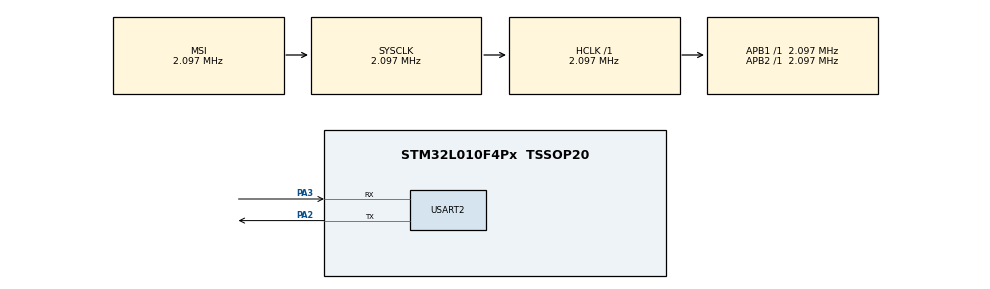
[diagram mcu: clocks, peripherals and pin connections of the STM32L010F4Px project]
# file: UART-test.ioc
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Mcu.Family=STM32L0
Mcu.Name=STM32L010F4Px
Mcu.Package=TSSOP20
NVIC.USART2_IRQn=true\:0\:0\:false\:false\:true\:true\:true
PA2.Mode=Asynchronous
PA2.Signal=USART2_TX
PA3.Mode=Asynchronous
PA3.Signal=USART2_RX
ProjectManager.HeapSize=0x200
ProjectManager.StackSize=0x400
ProjectManager.TargetToolchain=STM32CubeIDE
RCC.AHBFreq_Value=2097000
RCC.APB1Freq_Value=2097000
RCC.APB1TimFreq_Value=2097000
RCC.APB2Freq_Value=2097000
RCC.APB2TimFreq_Value=2097000
RCC.HSE_VALUE=8000000
RCC.HSI16_VALUE=16000000
RCC.HSI_VALUE=16000000
RCC.LSE_VALUE=32768
RCC.MSI_VALUE=2097000
RCC.SYSCLKFreq_VALUE=2097000
RCC.VCOOutputFreq_Value=48000000
USART2.VirtualMode=VM_ASYNC
board=custom

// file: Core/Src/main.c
/* USER CODE BEGIN Header */
/**
 ******************************************************************************
 * @file           : main.c
 * @brief          : Main program body
 ******************************************************************************
 * @attention
 *
 * <h2><center>&copy; Copyright (c) 2021 STMicroelectronics.
 * All rights reserved.</center></h2>
 *
 * This software component is licensed by ST under BSD 3-Clause license,
 * the "License"; You may not use this file except in compliance with the
 * License. You may obtain a copy of the License at:
 *                        opensource.org/licenses/BSD-3-Clause
 *
 ******************************************************************************
 */
/* USER CODE END Header */
#include "main.h"

/* USER CODE BEGIN Includes */
#define USART_RX_BUFFSIZE 10

static UART_HandleTypeDef *pHuart;
static uint8_t RxBuff[USART_RX_BUFFSIZE];
static uint32_t rd_ptr;

int gUartReceived = 0;
/* USER CODE END Includes */

UART_HandleTypeDef huart2;

void SystemClock_Config(void);
static void MX_GPIO_Init(void);
static void MX_USART2_UART_Init(void);
/* USER CODE BEGIN PFP */
void HAL_UART_RxCpltCallback(UART_HandleTypeDef *huart) {
	gUartReceived = 1;
}
/* USER CODE END PFP */

int main(void) {

	/* MCU Configuration--------------------------------------------------------*/

	/* Reset of all peripherals, Initializes the Flash interface and the Systick. */
	HAL_Init();

	/* Configure the system clock */
	SystemClock_Config();

	/* Initialize all configured peripherals */
	MX_GPIO_Init();
	MX_USART2_UART_Init();
	/* USER CODE BEGIN 2 */
	uint8_t buffer[256];
	/* USER CODE END 2 */

	/* Infinite loop */
	while (1) {

		/* USER CODE BEGIN 3 */
		HAL_UART_Receive_IT(&huart2, buffer, 1);
		HAL_UART_Transmit_IT(&huart2, buffer, 1);

		gUartReceived = 0;
	}
	/* USER CODE END 3 */
}

void SystemClock_Config(void) {
	RCC_OscInitTypeDef RCC_OscInitStruct = { 0 };
	RCC_ClkInitTypeDef RCC_ClkInitStruct = { 0 };
	RCC_PeriphCLKInitTypeDef PeriphClkInit = { 0 };

	/** Configure the main internal regulator output voltage
	 */
	__HAL_PWR_VOLTAGESCALING_CONFIG(PWR_REGULATOR_VOLTAGE_SCALE1);
	/** Initializes the RCC Oscillators according to the specified parameters
	 * in the RCC_OscInitTypeDef structure.
	 */
	RCC_OscInitStruct.OscillatorType = RCC_OSCILLATORTYPE_MSI;
	RCC_OscInitStruct.MSIState = RCC_MSI_ON;
	RCC_OscInitStruct.MSICalibrationValue = 0;
	RCC_OscInitStruct.MSIClockRange = RCC_MSIRANGE_5;
	RCC_OscInitStruct.PLL.PLLState = RCC_PLL_NONE;
	if (HAL_RCC_OscConfig(&RCC_OscInitStruct) != HAL_OK) {
		Error_Handler();
	}
	/** Initializes the CPU, AHB and APB buses clocks
	 */
	RCC_ClkInitStruct.ClockType = RCC_CLOCKTYPE_HCLK | RCC_CLOCKTYPE_SYSCLK
			| RCC_CLOCKTYPE_PCLK1 | RCC_CLOCKTYPE_PCLK2;
	RCC_ClkInitStruct.SYSCLKSource = RCC_SYSCLKSOURCE_MSI;
	RCC_ClkInitStruct.AHBCLKDivider = RCC_SYSCLK_DIV1;
	RCC_ClkInitStruct.APB1CLKDivider = RCC_HCLK_DIV1;
	RCC_ClkInitStruct.APB2CLKDivider = RCC_HCLK_DIV1;

	if (HAL_RCC_ClockConfig(&RCC_ClkInitStruct, FLASH_LATENCY_0) != HAL_OK) {
		Error_Handler();
	}
	PeriphClkInit.PeriphClockSelection = RCC_PERIPHCLK_USART2;
	PeriphClkInit.Usart2ClockSelection = RCC_USART2CLKSOURCE_PCLK1;
	if (HAL_RCCEx_PeriphCLKConfig(&PeriphClkInit) != HAL_OK) {
		Error_Handler();
	}
}

static void MX_USART2_UART_Init(void) {

	huart2.Instance = USART2;
	huart2.Init.BaudRate = 115200;
	huart2.Init.WordLength = UART_WORDLENGTH_8B;
	huart2.Init.StopBits = UART_STOPBITS_1;
	huart2.Init.Parity = UART_PARITY_NONE;
	huart2.Init.Mode = UART_MODE_TX_RX;
	huart2.Init.HwFlowCtl = UART_HWCONTROL_NONE;
	huart2.Init.OverSampling = UART_OVERSAMPLING_16;
	huart2.Init.OneBitSampling = UART_ONE_BIT_SAMPLE_DISABLE;
	huart2.AdvancedInit.AdvFeatureInit = UART_ADVFEATURE_NO_INIT;
	if (HAL_UART_Init(&huart2) != HAL_OK) {
		Error_Handler();
	}

}

static void MX_GPIO_Init(void) {

	/* GPIO Ports Clock Enable */
	__HAL_RCC_GPIOA_CLK_ENABLE();

}

void Error_Handler(void) {
	__disable_irq();
	while (1) {
	}
}

/************************ (C) COPYRIGHT STMicroelectronics *****END OF FILE****/
